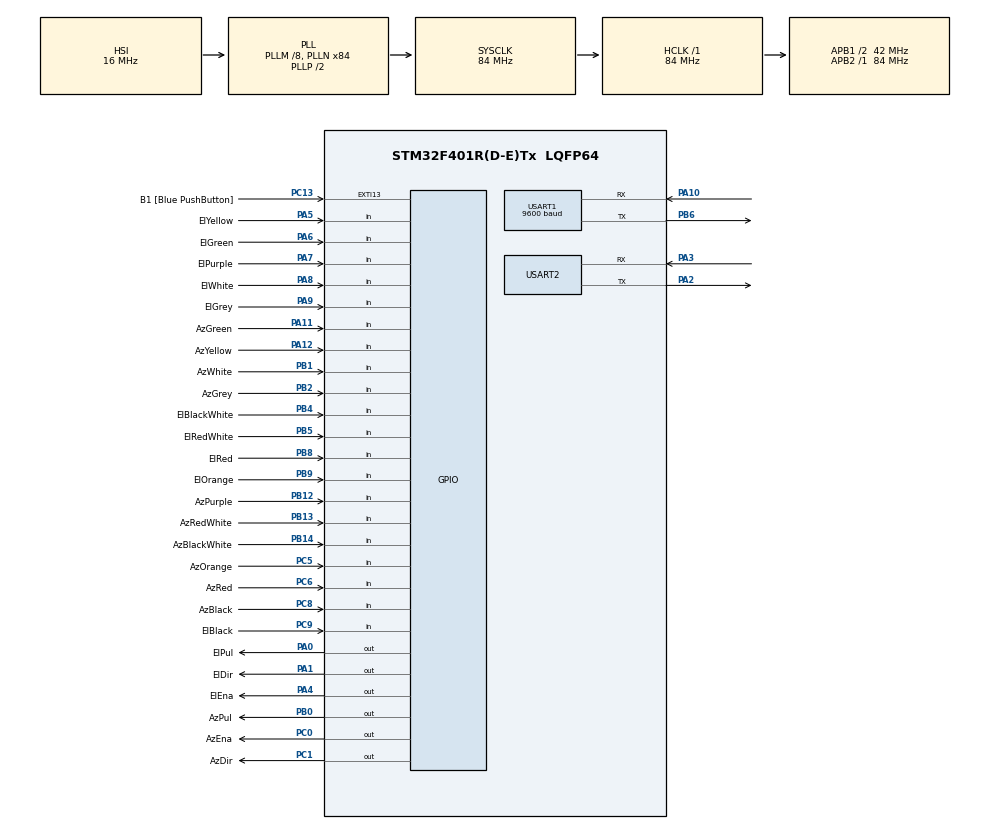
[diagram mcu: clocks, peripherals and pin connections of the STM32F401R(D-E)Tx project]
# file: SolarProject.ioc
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Mcu.Family=STM32F4
Mcu.Name=STM32F401R(D-E)Tx
Mcu.Package=LQFP64
NVIC.PriorityGroup=NVIC_PRIORITYGROUP_0
NVIC.TIM1_UP_TIM10_IRQn=true\:0\:0\:false\:false\:true\:true\:true
NVIC.TIM2_IRQn=true\:0\:0\:false\:false\:true\:true\:true
NVIC.USART1_IRQn=true\:0\:0\:false\:false\:true\:true\:true
PA0-WKUP.GPIO_Label=ElPul
PA0-WKUP.Signal=GPIO_Output
PA1.GPIO_Label=ElDir
PA1.Signal=GPIO_Output
PA10.Mode=Asynchronous
PA10.Signal=USART1_RX
PA11.GPIO_Label=AzGreen
PA11.GPIO_PuPd=GPIO_PULLUP
PA11.Signal=GPIO_Input
PA12.GPIO_Label=AzYellow
PA12.GPIO_PuPd=GPIO_PULLUP
PA12.Signal=GPIO_Input
PA13.GPIO_Label=TMS
PA13.Mode=Serial_Wire
PA13.Signal=SYS_JTMS-SWDIO
PA14.GPIO_Label=TCK
PA14.Mode=Serial_Wire
PA14.Signal=SYS_JTCK-SWCLK
PA2.Mode=Asynchronous
PA2.Signal=USART2_TX
PA3.Mode=Asynchronous
PA3.Signal=USART2_RX
PA4.GPIO_Label=ElEna
PA4.Signal=GPIO_Output
PA5.GPIO_Label=ElYellow
PA5.GPIO_PuPd=GPIO_PULLUP
PA5.Signal=GPIO_Input
PA6.GPIO_Label=ElGreen
PA6.GPIO_PuPd=GPIO_PULLUP
PA6.Signal=GPIO_Input
PA7.GPIO_Label=ElPurple
PA7.GPIO_PuPd=GPIO_PULLUP
PA7.Signal=GPIO_Input
PA8.GPIO_Label=ElWhite
PA8.GPIO_PuPd=GPIO_PULLUP
PA8.Signal=GPIO_Input
PA9.GPIO_Label=ElGrey
PA9.GPIO_PuPd=GPIO_PULLUP
PA9.Signal=GPIO_Input
PB0.GPIO_Label=AzPul
PB0.Signal=GPIO_Output
PB1.GPIO_Label=AzWhite
PB1.GPIO_PuPd=GPIO_PULLUP
PB1.Signal=GPIO_Input
PB10.GPIO_Label=I2C2_SCL_D6
PB10.Signal=I2C2_SCL
PB12.GPIO_Label=AzPurple
PB12.GPIO_PuPd=GPIO_PULLUP
PB12.Signal=GPIO_Input
PB13.GPIO_Label=AzRedWhite
PB13.GPIO_PuPd=GPIO_PULLUP
PB13.Signal=GPIO_Input
PB14.GPIO_Label=AzBlackWhite
PB14.GPIO_PuPd=GPIO_PULLUP
PB14.Signal=GPIO_Input
PB2.GPIO_Label=AzGrey
PB2.GPIO_PuPd=GPIO_PULLUP
PB2.Signal=GPIO_Input
PB3.GPIO_Label=I2C2_SDA_D3
PB3.Signal=I2C2_SDA
PB4.GPIO_Label=ElBlackWhite
PB4.GPIO_PuPd=GPIO_PULLUP
PB4.Signal=GPIO_Input
PB5.GPIO_Label=ElRedWhite
PB5.GPIO_PuPd=GPIO_PULLUP
PB5.Signal=GPIO_Input
PB6.Mode=Asynchronous
PB6.Signal=USART1_TX
PB8.GPIO_Label=ElRed
PB8.GPIO_PuPd=GPIO_PULLUP
PB8.Signal=GPIO_Input
PB9.GPIO_Label=ElOrange
PB9.GPIO_PuPd=GPIO_PULLUP
PB9.Signal=GPIO_Input
PC0.GPIO_Label=AzEna
PC0.Signal=GPIO_Output
PC1.GPIO_Label=AzDir
PC1.Signal=GPIO_Output
PC13-ANTI_TAMP.GPIO_Label=B1 [Blue PushButton]
PC13-ANTI_TAMP.GPIO_ModeDefaultEXTI=GPIO_MODE_IT_FALLING
PC13-ANTI_TAMP.GPIO_PuPd=GPIO_NOPULL
PC13-ANTI_TAMP.Signal=GPXTI13
PC14-OSC32_IN.Mode=LSE-External-Oscillator
PC14-OSC32_IN.Signal=RCC_OSC32_IN
PC15-OSC32_OUT.Mode=LSE-External-Oscillator
PC15-OSC32_OUT.Signal=RCC_OSC32_OUT
PC5.GPIO_Label=AzOrange
PC5.GPIO_PuPd=GPIO_PULLUP
PC5.Signal=GPIO_Input
PC6.GPIO_Label=AzRed
PC6.GPIO_PuPd=GPIO_PULLUP
PC6.Signal=GPIO_Input
PC8.GPIO_Label=AzBlack
PC8.GPIO_PuPd=GPIO_PULLUP
PC8.Signal=GPIO_Input
PC9.GPIO_Label=ElBlack
PC9.GPIO_PuPd=GPIO_PULLUP
PC9.Signal=GPIO_Input
PH0\ -\ OSC_IN.Signal=RCC_OSC_IN
PH1\ -\ OSC_OUT.Signal=RCC_OSC_OUT
ProjectManager.HeapSize=0x200
ProjectManager.StackSize=0x400
ProjectManager.TargetToolchain=STM32CubeIDE
RCC.48MHZClocksFreq_Value=24000000
RCC.AHBFreq_Value=84000000
RCC.APB1CLKDivider=RCC_HCLK_DIV2
RCC.APB1Freq_Value=42000000
RCC.APB1TimFreq_Value=84000000
RCC.APB2Freq_Value=84000000
RCC.APB2TimFreq_Value=84000000
RCC.CortexFreq_Value=84000000
RCC.HCLKFreq_Value=84000000
RCC.HSE_VALUE=8000000
RCC.HSI_VALUE=16000000
RCC.PLLM=8
RCC.PLLN=84
RCC.PLLQ=7
RCC.RCC_RTC_Clock_Source=RCC_RTCCLKSOURCE_LSE
RCC.RCC_RTC_Clock_SourceVirtual=RCC_RTCCLKSOURCE_LSE
RCC.SYSCLKFreq_VALUE=84000000
RCC.SYSCLKSource=RCC_SYSCLKSOURCE_PLLCLK
RCC.VCOOutputFreq_Value=168000000
TIM1.AutoReloadPreload=TIM_AUTORELOAD_PRELOAD_ENABLE
TIM1.CounterMode=TIM_COUNTERMODE_DOWN
TIM1.Period=0xffff
TIM1.Prescaler=1282
TIM2.AutoReloadPreload=TIM_AUTORELOAD_PRELOAD_ENABLE
TIM2.CounterMode=TIM_COUNTERMODE_DOWN
TIM2.Period=0xffff
TIM2.Prescaler=1282
USART1.BaudRate=9600
USART1.VirtualMode=VM_ASYNC
USART2.VirtualMode=VM_ASYNC
VP_TIM1_VS_ClockSourceINT.Mode=Internal
VP_TIM2_VS_ClockSourceINT.Mode=Internal
board=NUCLEO-F401RE

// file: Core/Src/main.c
/* USER CODE BEGIN Header */
/**
  ******************************************************************************
  * @file           : main.c
  * @brief          : Main program body
  ******************************************************************************
  * @attention
  *
  * <h2><center>&copy; Copyright (c) 2020 STMicroelectronics.
  * All rights reserved.</center></h2>
  *
  * This software component is licensed by ST under BSD 3-Clause license,
  * the "License"; You may not use this file except in compliance with the
  * License. You may obtain a copy of the License at:
  *                        opensource.org/licenses/BSD-3-Clause
  *
  ******************************************************************************
  */
/* USER CODE END Header */
#include "main.h"

TIM_HandleTypeDef htim1;
TIM_HandleTypeDef htim2;

UART_HandleTypeDef huart1;
UART_HandleTypeDef huart2;

void SystemClock_Config(void);
static void MX_GPIO_Init(void);
static void MX_TIM1_Init(void);
static void MX_TIM2_Init(void);
static void MX_USART2_UART_Init(void);
static void MX_USART1_UART_Init(void);

int main(void)
{

  /* MCU Configuration--------------------------------------------------------*/

  /* Reset of all peripherals, Initializes the Flash interface and the Systick. */
  HAL_Init();

  /* Configure the system clock */
  SystemClock_Config();

  /* Initialize all configured peripherals */
  MX_GPIO_Init();
  MX_TIM1_Init();
  MX_TIM2_Init();
  MX_USART2_UART_Init();
  MX_USART1_UART_Init();
  /* USER CODE BEGIN 2 */
  __HAL_UART_ENABLE_IT(&huart1, UART_IT_RXNE); //enable gps uart recieve interrupt
  HAL_TIM_Base_Start_IT(&htim1); //enable steppers
  HAL_TIM_Base_Start_IT(&htim2); //enable steppers
  mainsetup();
  /* USER CODE END 2 */

  /* Infinite loop */
  /* USER CODE BEGIN WHILE */
  while (1)
  {
	  mainloop();
    /* USER CODE END WHILE */

  }
}

void SystemClock_Config(void)
{
  RCC_OscInitTypeDef RCC_OscInitStruct = {0};
  RCC_ClkInitTypeDef RCC_ClkInitStruct = {0};

  /** Configure the main internal regulator output voltage
  */
  __HAL_RCC_PWR_CLK_ENABLE();
  __HAL_PWR_VOLTAGESCALING_CONFIG(PWR_REGULATOR_VOLTAGE_SCALE2);
  /** Initializes the RCC Oscillators according to the specified parameters
  * in the RCC_OscInitTypeDef structure.
  */
  RCC_OscInitStruct.OscillatorType = RCC_OSCILLATORTYPE_HSI;
  RCC_OscInitStruct.HSIState = RCC_HSI_ON;
  RCC_OscInitStruct.HSICalibrationValue = RCC_HSICALIBRATION_DEFAULT;
  RCC_OscInitStruct.PLL.PLLState = RCC_PLL_ON;
  RCC_OscInitStruct.PLL.PLLSource = RCC_PLLSOURCE_HSI;
  RCC_OscInitStruct.PLL.PLLM = 8;
  RCC_OscInitStruct.PLL.PLLN = 84;
  RCC_OscInitStruct.PLL.PLLP = RCC_PLLP_DIV2;
  RCC_OscInitStruct.PLL.PLLQ = 7;
  if (HAL_RCC_OscConfig(&RCC_OscInitStruct) != HAL_OK)
  {
    Error_Handler();
  }
  /** Initializes the CPU, AHB and APB buses clocks
  */
  RCC_ClkInitStruct.ClockType = RCC_CLOCKTYPE_HCLK|RCC_CLOCKTYPE_SYSCLK
                              |RCC_CLOCKTYPE_PCLK1|RCC_CLOCKTYPE_PCLK2;
  RCC_ClkInitStruct.SYSCLKSource = RCC_SYSCLKSOURCE_PLLCLK;
  RCC_ClkInitStruct.AHBCLKDivider = RCC_SYSCLK_DIV1;
  RCC_ClkInitStruct.APB1CLKDivider = RCC_HCLK_DIV2;
  RCC_ClkInitStruct.APB2CLKDivider = RCC_HCLK_DIV1;

  if (HAL_RCC_ClockConfig(&RCC_ClkInitStruct, FLASH_LATENCY_2) != HAL_OK)
  {
    Error_Handler();
  }
}

static void MX_TIM1_Init(void)
{

  TIM_ClockConfigTypeDef sClockSourceConfig = {0};
  TIM_MasterConfigTypeDef sMasterConfig = {0};

  htim1.Instance = TIM1;
  htim1.Init.Prescaler = 1282;
  htim1.Init.CounterMode = TIM_COUNTERMODE_DOWN;
  htim1.Init.Period = 0xffff;
  htim1.Init.ClockDivision = TIM_CLOCKDIVISION_DIV1;
  htim1.Init.RepetitionCounter = 0;
  htim1.Init.AutoReloadPreload = TIM_AUTORELOAD_PRELOAD_ENABLE;
  if (HAL_TIM_Base_Init(&htim1) != HAL_OK)
  {
    Error_Handler();
  }
  sClockSourceConfig.ClockSource = TIM_CLOCKSOURCE_INTERNAL;
  if (HAL_TIM_ConfigClockSource(&htim1, &sClockSourceConfig) != HAL_OK)
  {
    Error_Handler();
  }
  sMasterConfig.MasterOutputTrigger = TIM_TRGO_RESET;
  sMasterConfig.MasterSlaveMode = TIM_MASTERSLAVEMODE_DISABLE;
  if (HAL_TIMEx_MasterConfigSynchronization(&htim1, &sMasterConfig) != HAL_OK)
  {
    Error_Handler();
  }

}

static void MX_TIM2_Init(void)
{

  TIM_ClockConfigTypeDef sClockSourceConfig = {0};
  TIM_MasterConfigTypeDef sMasterConfig = {0};

  htim2.Instance = TIM2;
  htim2.Init.Prescaler = 1282;
  htim2.Init.CounterMode = TIM_COUNTERMODE_DOWN;
  htim2.Init.Period = 0xffff;
  htim2.Init.ClockDivision = TIM_CLOCKDIVISION_DIV1;
  htim2.Init.AutoReloadPreload = TIM_AUTORELOAD_PRELOAD_ENABLE;
  if (HAL_TIM_Base_Init(&htim2) != HAL_OK)
  {
    Error_Handler();
  }
  sClockSourceConfig.ClockSource = TIM_CLOCKSOURCE_INTERNAL;
  if (HAL_TIM_ConfigClockSource(&htim2, &sClockSourceConfig) != HAL_OK)
  {
    Error_Handler();
  }
  sMasterConfig.MasterOutputTrigger = TIM_TRGO_RESET;
  sMasterConfig.MasterSlaveMode = TIM_MASTERSLAVEMODE_DISABLE;
  if (HAL_TIMEx_MasterConfigSynchronization(&htim2, &sMasterConfig) != HAL_OK)
  {
    Error_Handler();
  }

}

static void MX_USART1_UART_Init(void)
{

  huart1.Instance = USART1;
  huart1.Init.BaudRate = 9600;
  huart1.Init.WordLength = UART_WORDLENGTH_8B;
  huart1.Init.StopBits = UART_STOPBITS_1;
  huart1.Init.Parity = UART_PARITY_NONE;
  huart1.Init.Mode = UART_MODE_TX_RX;
  huart1.Init.HwFlowCtl = UART_HWCONTROL_NONE;
  huart1.Init.OverSampling = UART_OVERSAMPLING_16;
  if (HAL_UART_Init(&huart1) != HAL_OK)
  {
    Error_Handler();
  }

}

static void MX_USART2_UART_Init(void)
{

  huart2.Instance = USART2;
  huart2.Init.BaudRate = 115200;
  huart2.Init.WordLength = UART_WORDLENGTH_8B;
  huart2.Init.StopBits = UART_STOPBITS_1;
  huart2.Init.Parity = UART_PARITY_NONE;
  huart2.Init.Mode = UART_MODE_TX_RX;
  huart2.Init.HwFlowCtl = UART_HWCONTROL_NONE;
  huart2.Init.OverSampling = UART_OVERSAMPLING_16;
  if (HAL_UART_Init(&huart2) != HAL_OK)
  {
    Error_Handler();
  }

}

static void MX_GPIO_Init(void)
{
  GPIO_InitTypeDef GPIO_InitStruct = {0};

  /* GPIO Ports Clock Enable */
  __HAL_RCC_GPIOC_CLK_ENABLE();
  __HAL_RCC_GPIOH_CLK_ENABLE();
  __HAL_RCC_GPIOA_CLK_ENABLE();
  __HAL_RCC_GPIOB_CLK_ENABLE();

  /*Configure GPIO pin Output Level */
  HAL_GPIO_WritePin(GPIOC, AzEna_Pin|AzDir_Pin, GPIO_PIN_RESET);

  /*Configure GPIO pin Output Level */
  HAL_GPIO_WritePin(GPIOA, ElPul_Pin|ElDir_Pin|ElEna_Pin, GPIO_PIN_RESET);

  /*Configure GPIO pin Output Level */
  HAL_GPIO_WritePin(AzPul_GPIO_Port, AzPul_Pin, GPIO_PIN_RESET);

  /*Configure GPIO pin : B1_Pin */
  GPIO_InitStruct.Pin = B1_Pin;
  GPIO_InitStruct.Mode = GPIO_MODE_IT_FALLING;
  GPIO_InitStruct.Pull = GPIO_NOPULL;
  HAL_GPIO_Init(B1_GPIO_Port, &GPIO_InitStruct);

  /*Configure GPIO pins : AzEna_Pin AzDir_Pin */
  GPIO_InitStruct.Pin = AzEna_Pin|AzDir_Pin;
  GPIO_InitStruct.Mode = GPIO_MODE_OUTPUT_PP;
  GPIO_InitStruct.Pull = GPIO_NOPULL;
  GPIO_InitStruct.Speed = GPIO_SPEED_FREQ_LOW;
  HAL_GPIO_Init(GPIOC, &GPIO_InitStruct);

  /*Configure GPIO pins : ElPul_Pin ElDir_Pin ElEna_Pin */
  GPIO_InitStruct.Pin = ElPul_Pin|ElDir_Pin|ElEna_Pin;
  GPIO_InitStruct.Mode = GPIO_MODE_OUTPUT_PP;
  GPIO_InitStruct.Pull = GPIO_NOPULL;
  GPIO_InitStruct.Speed = GPIO_SPEED_FREQ_LOW;
  HAL_GPIO_Init(GPIOA, &GPIO_InitStruct);

  /*Configure GPIO pins : ElYellow_Pin ElGreen_Pin ElPurple_Pin ElWhite_Pin
                           ElGrey_Pin AzGreen_Pin AzYellow_Pin */
  GPIO_InitStruct.Pin = ElYellow_Pin|ElGreen_Pin|ElPurple_Pin|ElWhite_Pin
                          |ElGrey_Pin|AzGreen_Pin|AzYellow_Pin;
  GPIO_InitStruct.Mode = GPIO_MODE_INPUT;
  GPIO_InitStruct.Pull = GPIO_PULLUP;
  HAL_GPIO_Init(GPIOA, &GPIO_InitStruct);

  /*Configure GPIO pins : AzOrange_Pin AzRed_Pin AzBlack_Pin ElBlack_Pin */
  GPIO_InitStruct.Pin = AzOrange_Pin|AzRed_Pin|AzBlack_Pin|ElBlack_Pin;
  GPIO_InitStruct.Mode = GPIO_MODE_INPUT;
  GPIO_InitStruct.Pull = GPIO_PULLUP;
  HAL_GPIO_Init(GPIOC, &GPIO_InitStruct);

  /*Configure GPIO pin : AzPul_Pin */
  GPIO_InitStruct.Pin = AzPul_Pin;
  GPIO_InitStruct.Mode = GPIO_MODE_OUTPUT_PP;
  GPIO_InitStruct.Pull = GPIO_NOPULL;
  GPIO_InitStruct.Speed = GPIO_SPEED_FREQ_LOW;
  HAL_GPIO_Init(AzPul_GPIO_Port, &GPIO_InitStruct);

  /*Configure GPIO pins : AzWhite_Pin AzGrey_Pin AzPurple_Pin AzRedWhite_Pin
                           AzBlackWhite_Pin ElBlackWhite_Pin ElRedWhite_Pin ElRed_Pin
                           ElOrange_Pin */
  GPIO_InitStruct.Pin = AzWhite_Pin|AzGrey_Pin|AzPurple_Pin|AzRedWhite_Pin
                          |AzBlackWhite_Pin|ElBlackWhite_Pin|ElRedWhite_Pin|ElRed_Pin
                          |ElOrange_Pin;
  GPIO_InitStruct.Mode = GPIO_MODE_INPUT;
  GPIO_InitStruct.Pull = GPIO_PULLUP;
  HAL_GPIO_Init(GPIOB, &GPIO_InitStruct);

  /*Configure GPIO pin : I2C2_SCL_D6_Pin */
  GPIO_InitStruct.Pin = I2C2_SCL_D6_Pin;
  GPIO_InitStruct.Mode = GPIO_MODE_AF_OD;
  GPIO_InitStruct.Pull = GPIO_PULLUP;
  GPIO_InitStruct.Speed = GPIO_SPEED_FREQ_VERY_HIGH;
  GPIO_InitStruct.Alternate = GPIO_AF4_I2C2;
  HAL_GPIO_Init(I2C2_SCL_D6_GPIO_Port, &GPIO_InitStruct);

  /*Configure GPIO pin : I2C2_SDA_D3_Pin */
  GPIO_InitStruct.Pin = I2C2_SDA_D3_Pin;
  GPIO_InitStruct.Mode = GPIO_MODE_AF_OD;
  GPIO_InitStruct.Pull = GPIO_PULLUP;
  GPIO_InitStruct.Speed = GPIO_SPEED_FREQ_VERY_HIGH;
  GPIO_InitStruct.Alternate = GPIO_AF9_I2C2;
  HAL_GPIO_Init(I2C2_SDA_D3_GPIO_Port, &GPIO_InitStruct);

}

void Error_Handler(void)
{
  __disable_irq();
  while (1)
  {
  }
}

/************************ (C) COPYRIGHT STMicroelectronics *****END OF FILE****/
